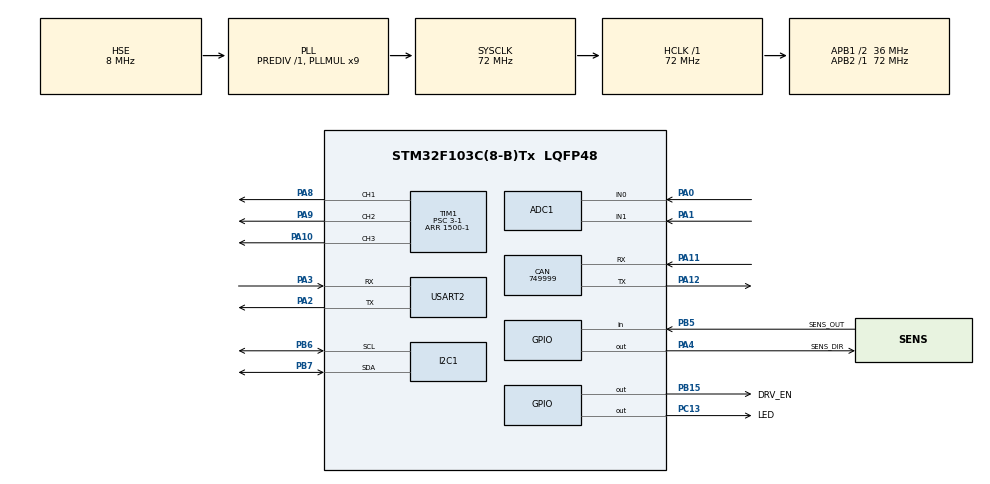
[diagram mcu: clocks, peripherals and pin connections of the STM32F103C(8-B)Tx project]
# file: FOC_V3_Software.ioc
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ADC1.Channel-0\#ChannelRegularConversion=ADC_CHANNEL_0
ADC1.NbrOfConversionFlag=1
ADC1.Rank-0\#ChannelRegularConversion=1
ADC1.SamplingTime-0\#ChannelRegularConversion=ADC_SAMPLETIME_1CYCLE_5
ADC1.master=1
CAN.CalculateBaudRate=749999
CAN.CalculateTimeBit=1333
CAN.CalculateTimeQuantum=444.44444444444446
Mcu.Family=STM32F1
Mcu.Name=STM32F103C(8-B)Tx
Mcu.Package=LQFP48
NVIC.PriorityGroup=NVIC_PRIORITYGROUP_4
PA0-WKUP.Signal=ADCx_IN0
PA1.Signal=ADCx_IN1
PA10.Signal=S_TIM1_CH3
PA11.Mode=CAN_Activate
PA11.Signal=CAN_RX
PA12.Mode=CAN_Activate
PA12.Signal=CAN_TX
PA13.Mode=Serial_Wire
PA13.Signal=SYS_JTMS-SWDIO
PA14.Mode=Serial_Wire
PA14.Signal=SYS_JTCK-SWCLK
PA2.Mode=Asynchronous
PA2.Signal=USART2_TX
PA3.Mode=Asynchronous
PA3.Signal=USART2_RX
PA4.GPIO_Label=SENS_DIR
PA4.Signal=GPIO_Output
PA8.Signal=S_TIM1_CH1
PA9.Signal=S_TIM1_CH2
PB15.GPIO_Label=DRV_EN
PB15.Signal=GPIO_Output
PB5.GPIO_Label=SENS_OUT
PB5.Signal=GPIO_Input
PB6.Mode=I2C
PB6.Signal=I2C1_SCL
PB7.Mode=I2C
PB7.Signal=I2C1_SDA
PC13-TAMPER-RTC.GPIO_Label=LED
PC13-TAMPER-RTC.Signal=GPIO_Output
PD0-OSC_IN.Mode=HSE-External-Oscillator
PD0-OSC_IN.Signal=RCC_OSC_IN
PD1-OSC_OUT.Mode=HSE-External-Oscillator
PD1-OSC_OUT.Signal=RCC_OSC_OUT
ProjectManager.HeapSize=0x200
ProjectManager.StackSize=0x400
ProjectManager.TargetToolchain=MDK-ARM V5
RCC.ADCPresc=RCC_ADCPCLK2_DIV6
RCC.AHBFreq_Value=72000000
RCC.APB1CLKDivider=RCC_HCLK_DIV2
RCC.APB1Freq_Value=36000000
RCC.APB1TimFreq_Value=72000000
RCC.APB2Freq_Value=72000000
RCC.APB2TimFreq_Value=72000000
RCC.HCLKFreq_Value=72000000
RCC.PLLMUL=RCC_PLL_MUL9
RCC.PLLSourceVirtual=RCC_PLLSOURCE_HSE
RCC.SYSCLKFreq_VALUE=72000000
RCC.SYSCLKSource=RCC_SYSCLKSOURCE_PLLCLK
RCC.USBFreq_Value=72000000
SH.ADCx_IN0.0=ADC1_IN0,IN0
SH.ADCx_IN1.0=ADC1_IN1,IN1
SH.S_TIM1_CH1.0=TIM1_CH1,PWM Generation1 CH1
SH.S_TIM1_CH2.0=TIM1_CH2,PWM Generation2 CH2
SH.S_TIM1_CH3.0=TIM1_CH3,PWM Generation3 CH3
TIM1.AutoReloadPreload=TIM_AUTORELOAD_PRELOAD_ENABLE
TIM1.Channel-PWM\ Generation1\ CH1=TIM_CHANNEL_1
TIM1.Channel-PWM\ Generation2\ CH2=TIM_CHANNEL_2
TIM1.Channel-PWM\ Generation3\ CH3=TIM_CHANNEL_3
TIM1.Period=1500-1
TIM1.Prescaler=3-1
TIM2.Period=240-1
TIM2.Prescaler=300-1
TIM3.Period=240-1
TIM3.Prescaler=300-1
TIM4.Period=240-1
TIM4.Prescaler=300-1
USART2.VirtualMode=VM_ASYNC
VP_TIM1_VS_ClockSourceINT.Mode=Internal
VP_TIM2_VS_ClockSourceINT.Mode=Internal
VP_TIM3_VS_ClockSourceINT.Mode=Internal
VP_TIM4_VS_ClockSourceINT.Mode=Internal
board=custom

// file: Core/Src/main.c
/* USER CODE BEGIN Header */
/**
  ******************************************************************************
  * @file           : main.c
  * @brief          : Main program body
  ******************************************************************************
  * @attention
  *
  * Copyright (c) 2022 STMicroelectronics.
  * All rights reserved.
  *
  * This software is licensed under terms that can be found in the LICENSE file
  * in the root directory of this software component.
  * If no LICENSE file comes with this software, it is provided AS-IS.
  *
  ******************************************************************************
  */
/* USER CODE END Header */
#include "main.h"
#include "adc.h"
#include "can.h"
#include "i2c.h"
#include "tim.h"
#include "usart.h"
#include "gpio.h"

/* USER CODE BEGIN Includes */

#include "stdio.h"

int fgetc(FILE *f) {
	uint8_t ch = 0;
	HAL_UART_Receive(&huart2,&ch,1,0xffff);
	return ch;
}

int fputc(int ch, FILE *f) {
	HAL_UART_Transmit(&huart2,(uint8_t *)&ch,1,0xffff);
	return ch;
}

/* USER CODE END Includes */

void SystemClock_Config(void);

int main(void)
{

  /* MCU Configuration--------------------------------------------------------*/

  /* Reset of all peripherals, Initializes the Flash interface and the Systick. */
  HAL_Init();

  /* Configure the system clock */
  SystemClock_Config();

  /* Initialize all configured peripherals */
  MX_GPIO_Init();
  MX_ADC1_Init();
  MX_CAN_Init();
  MX_I2C1_Init();
  MX_TIM1_Init();
  MX_TIM2_Init();
  MX_TIM3_Init();
  MX_TIM4_Init();
  MX_USART2_UART_Init();
  /* USER CODE BEGIN 2 */

    HAL_GPIO_WritePin(LED_GPIO_Port, LED_Pin, GPIO_PIN_RESET);
    HAL_Delay(1000);
  /* USER CODE END 2 */

  /* Infinite loop */
  /* USER CODE BEGIN WHILE */
  while (1)
  {
      printf("hello, world!\r\n");
      HAL_GPIO_TogglePin(LED_GPIO_Port, LED_Pin);
      HAL_GPIO_TogglePin(SENS_DIR_GPIO_Port, SENS_DIR_Pin);
      HAL_Delay(1000);
    /* USER CODE END WHILE */

  }
}

void SystemClock_Config(void)
{
  RCC_OscInitTypeDef RCC_OscInitStruct = {0};
  RCC_ClkInitTypeDef RCC_ClkInitStruct = {0};
  RCC_PeriphCLKInitTypeDef PeriphClkInit = {0};

  /** Initializes the RCC Oscillators according to the specified parameters
  * in the RCC_OscInitTypeDef structure.
  */
  RCC_OscInitStruct.OscillatorType = RCC_OSCILLATORTYPE_HSE;
  RCC_OscInitStruct.HSEState = RCC_HSE_ON;
  RCC_OscInitStruct.HSEPredivValue = RCC_HSE_PREDIV_DIV1;
  RCC_OscInitStruct.HSIState = RCC_HSI_ON;
  RCC_OscInitStruct.PLL.PLLState = RCC_PLL_ON;
  RCC_OscInitStruct.PLL.PLLSource = RCC_PLLSOURCE_HSE;
  RCC_OscInitStruct.PLL.PLLMUL = RCC_PLL_MUL9;
  if (HAL_RCC_OscConfig(&RCC_OscInitStruct) != HAL_OK)
  {
    Error_Handler();
  }

  /** Initializes the CPU, AHB and APB buses clocks
  */
  RCC_ClkInitStruct.ClockType = RCC_CLOCKTYPE_HCLK|RCC_CLOCKTYPE_SYSCLK
                              |RCC_CLOCKTYPE_PCLK1|RCC_CLOCKTYPE_PCLK2;
  RCC_ClkInitStruct.SYSCLKSource = RCC_SYSCLKSOURCE_PLLCLK;
  RCC_ClkInitStruct.AHBCLKDivider = RCC_SYSCLK_DIV1;
  RCC_ClkInitStruct.APB1CLKDivider = RCC_HCLK_DIV2;
  RCC_ClkInitStruct.APB2CLKDivider = RCC_HCLK_DIV1;

  if (HAL_RCC_ClockConfig(&RCC_ClkInitStruct, FLASH_LATENCY_2) != HAL_OK)
  {
    Error_Handler();
  }
  PeriphClkInit.PeriphClockSelection = RCC_PERIPHCLK_ADC;
  PeriphClkInit.AdcClockSelection = RCC_ADCPCLK2_DIV6;
  if (HAL_RCCEx_PeriphCLKConfig(&PeriphClkInit) != HAL_OK)
  {
    Error_Handler();
  }
}

void Error_Handler(void)
{
  __disable_irq();
  while (1)
  {
  }
}
